# ATSAMA5D31 register map
Vendor: Microchip Technology; Series: SAMA5D3; File version: 0
Registers are 32-bit, read-write, reset 0x0 unless marked. A register's access mark holds for its fields unless they carry their own. Offsets are from the block's base; [hi:lo] are bit positions; {n}, {i} and the like mark numbered series.

## TDES — Triple Data Encryption Standard
Base 0xF803C000
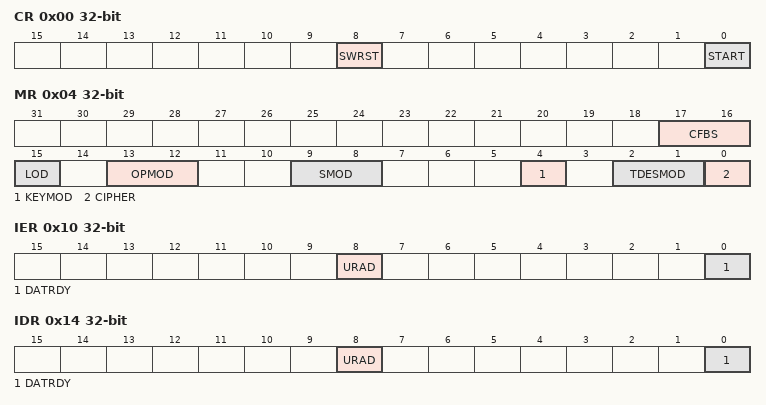
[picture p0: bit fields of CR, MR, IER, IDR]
0x00 CR wo — Control Register
  [8] SWRST — Software Reset
  [0] START — Start Processing
0x04 MR — Mode Register
  [17:16] CFBS — Cipher Feedback Data Size
    0=SIZE_64BIT (64-bit); 1=SIZE_32BIT (32-bit); 2=SIZE_16BIT (16-bit); 3=SIZE_8BIT (8-bit)
  [15] LOD — Last Output Data Mode
  [13:12] OPMOD — Operating Mode
    0=ECB (Electronic Code Book mode); 1=CBC (Cipher Block Chaining mode); 2=OFB (Output Feedback mode); 3=CFB (Cipher Feedback mode)
  [9:8] SMOD — Start Mode
    0=MANUAL_START (Manual Mode); 1=AUTO_START (Auto Mode); 2=IDATAR0_START (TDES_IDATAR0 accesses only Auto Mode)
  [4] KEYMOD — Key Mode
  [2:1] TDESMOD — ALGORITHM Mode
    0=SINGLE_DES (Single DES processing using TDES_KEY1WRx registers); 1=TRIPLE_DES (Triple DES processing using TDES_KEY1WRx, TDES_KEY2WRx and TDES_KEY3WRx registers); 2=XTEA (XTEA processing using TDES_KEY1WRx, TDES_KEY2WRx)
  [0] CIPHER — Processing Mode
    0=DECRYPT (Decrypts data.); 1=ENCRYPT (Encrypts data.)
0x10 IER wo — Interrupt Enable Register
  [8] URAD — Unspecified Register Access Detection Interrupt Enable
  [0] DATRDY — Data Ready Interrupt Enable
0x14 IDR wo — Interrupt Disable Register
  [8] URAD — Unspecified Register Access Detection Interrupt Disable
  [0] DATRDY — Data Ready Interrupt Disable
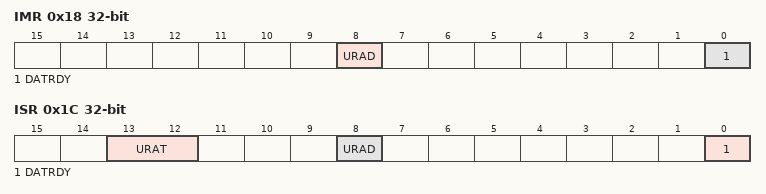
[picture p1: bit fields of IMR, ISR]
0x18 IMR ro — Interrupt Mask Register
  [8] URAD — Unspecified Register Access Detection Interrupt Mask
  [0] DATRDY — Data Ready Interrupt Mask
0x1C ISR ro — Interrupt Status Register
  [13:12] URAT — Unspecified Register Access (cleared by setting bit TDES_CR.SWRST)
    0=IDR_WR_PROCESSING (Input Data Register written during data processing when SMOD = 0x2 mode.); 1=ODR_RD_PROCESSING (Output Data Register read during data processing.); 2=MR_WR_PROCESSING (Mode Register written during data processing.); 3=WOR_RD_ACCESS (Write-only register read access.)
  [8] URAD — Unspecified Register Access Detection Status (cleared by setting bit TDES_CR.SWRST)
  [0] DATRDY — Data Ready (cleared by setting bit START or bit SWRST in TDES_CR or by reading TDES_ODATARx)
{0x20+4i} KEY1WR[{i}] (i=0..1) wo — Key 1 Word Register
  [31:0] KEY1W — Key 1 Word
{0x28+4i} KEY2WR[{i}] (i=0..1) wo — Key 2 Word Register
  [31:0] KEY2W — Key 2 Word
{0x30+4i} KEY3WR[{i}] (i=0..1) wo — Key 3 Word Register
  [31:0] KEY3W — Key 3 Word
{0x40+4i} IDATAR[{i}] (i=0..1) wo — Input Data Register
  [31:0] IDATA — Input Data
{0x50+4i} ODATAR[{i}] (i=0..1) ro — Output Data Register
  [31:0] ODATA — Output Data
{0x60+4i} IVR[{i}] (i=0..1) wo — Initialization Vector Register
  [31:0] IV — Initialization Vector
0x70 XTEA_RNDR — XTEA Rounds Register
  [5:0] XTEA_RNDS — Number of Rounds

## TRNG — True Random Number Generator
Base 0xF8040000
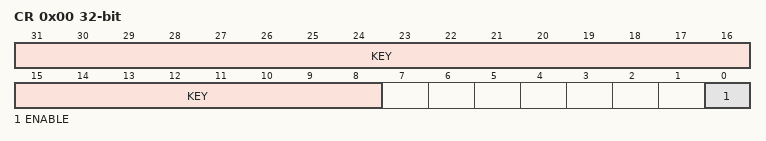
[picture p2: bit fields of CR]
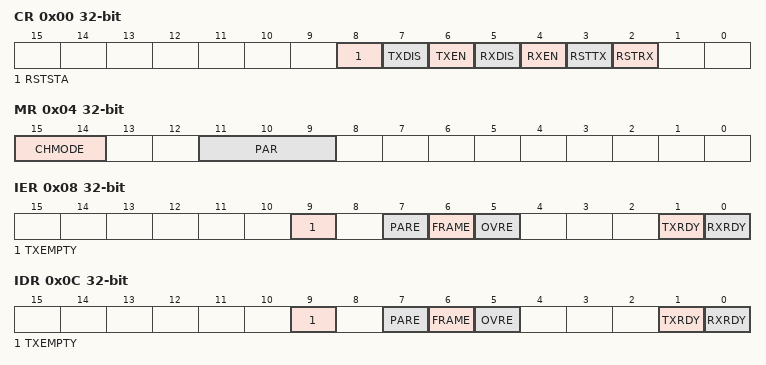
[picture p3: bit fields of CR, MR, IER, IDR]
0x00 CR wo — Control Register
  [31:8] KEY — Security Key
    0x524E47=PASSWD (Writing any other value in this field aborts the write operation.)
  [0] ENABLE — Enables the TRNG to Provide Random Values
0x10 IER wo — Interrupt Enable Register
  [0] DATRDY — Data Ready Interrupt Enable
0x14 IDR wo — Interrupt Disable Register
  [0] DATRDY — Data Ready Interrupt Disable
0x18 IMR ro — Interrupt Mask Register
  [0] DATRDY — Data Ready Interrupt Mask
0x1C ISR ro — Interrupt Status Register
  [0] DATRDY — Data Ready
0x50 ODATA ro — Output Data Register
  [31:0] ODATA — Output Data

## UART0 — Universal Asynchronous Receiver Transmitter
Base 0xF0024000; register names take the prefix UART_
Same registers: UART1 0xF8028000
0x00 CR wo — Control Register
  [8] RSTSTA — Reset Status
  [7] TXDIS — Transmitter Disable
  [6] TXEN — Transmitter Enable
  [5] RXDIS — Receiver Disable
  [4] RXEN — Receiver Enable
  [3] RSTTX — Reset Transmitter
  [2] RSTRX — Reset Receiver
0x04 MR — Mode Register
  [15:14] CHMODE — Channel Mode
    0=NORMAL (Normal mode); 1=AUTOMATIC (Automatic echo); 2=LOCAL_LOOPBACK; 3=REMOTE_LOOPBACK
  [11:9] PAR — Parity Type
    0=EVEN (Even Parity); 1=ODD (Odd Parity); 2=SPACE (Space: parity forced to 0); 3=MARK (Mark: parity forced to 1); 4=NO (No parity)
0x08 IER wo — Interrupt Enable Register
  [9] TXEMPTY — Enable TXEMPTY Interrupt
  [7] PARE — Enable Parity Error Interrupt
  [6] FRAME — Enable Framing Error Interrupt
  [5] OVRE — Enable Overrun Error Interrupt
  [1] TXRDY — Enable TXRDY Interrupt
  [0] RXRDY — Enable RXRDY Interrupt
0x0C IDR wo — Interrupt Disable Register
  [9] TXEMPTY — Disable TXEMPTY Interrupt
  [7] PARE — Disable Parity Error Interrupt
  [6] FRAME — Disable Framing Error Interrupt
  [5] OVRE — Disable Overrun Error Interrupt
  [1] TXRDY — Disable TXRDY Interrupt
  [0] RXRDY — Disable RXRDY Interrupt
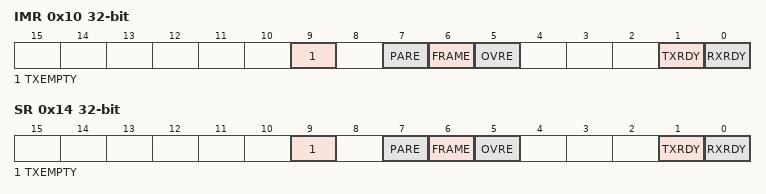
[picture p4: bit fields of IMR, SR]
0x10 IMR ro — Interrupt Mask Register
  [9] TXEMPTY — Mask TXEMPTY Interrupt
  [7] PARE — Mask Parity Error Interrupt
  [6] FRAME — Mask Framing Error Interrupt
  [5] OVRE — Mask Overrun Error Interrupt
  [1] TXRDY — Disable TXRDY Interrupt
  [0] RXRDY — Mask RXRDY Interrupt
0x14 SR ro — Status Register
  [9] TXEMPTY — Transmitter Empty
  [7] PARE — Parity Error
  [6] FRAME — Framing Error
  [5] OVRE — Overrun Error
  [1] TXRDY — Transmitter Ready
  [0] RXRDY — Receiver Ready
0x18 RHR ro — Receive Holding Register
  [7:0] RXCHR — Received Character
0x1C THR wo — Transmit Holding Register
  [7:0] TXCHR — Character to be Transmitted
0x20 BRGR — Baud Rate Generator Register
  [15:0] CD — Clock Divisor

## WDT — Watchdog Timer
Base 0xFFFFFE40
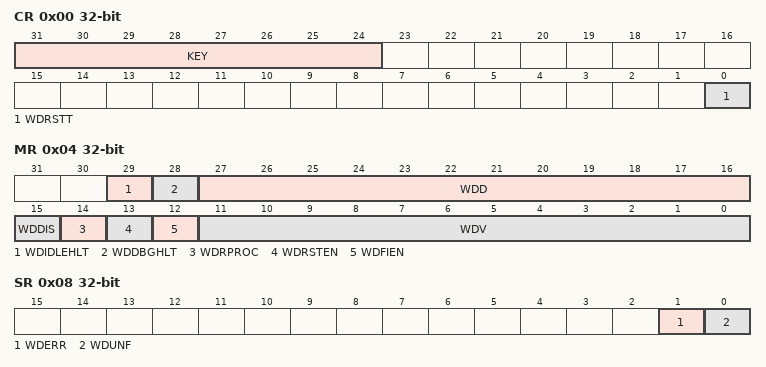
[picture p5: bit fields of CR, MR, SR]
0x00 CR wo — Control Register
  [31:24] KEY — Password
    165=PASSWD (Writing any other value in this field aborts the write operation.)
  [0] WDRSTT — Watchdog Restart
0x04 MR — Mode Register
  [29] WDIDLEHLT — Watchdog Idle Halt
  [28] WDDBGHLT — Watchdog Debug Halt
  [27:16] WDD — Watchdog Delta Value
  [15] WDDIS — Watchdog Disable
  [14] WDRPROC — Watchdog Reset Processor
  [13] WDRSTEN — Watchdog Reset Enable
  [12] WDFIEN — Watchdog Fault Interrupt Enable
  [11:0] WDV — Watchdog Counter Value
0x08 SR ro — Status Register
  [1] WDERR — Watchdog Error (cleared on read)
  [0] WDUNF — Watchdog Underflow (cleared on read)
